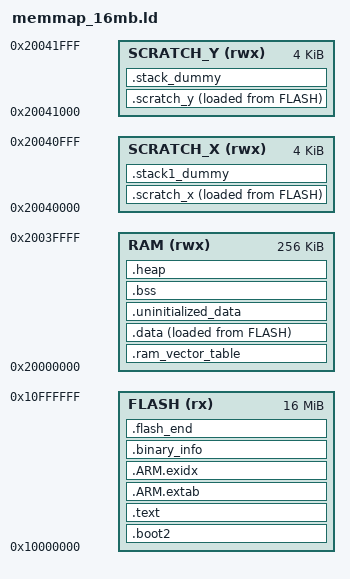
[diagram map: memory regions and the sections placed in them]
/* memmap_16mb.ld — Custom linker script for YD-RP2040 / WeAct RP2040
 * with 16 MB Flash (W25Q128JVSIQ or similar)
 *
 * Based on Pico SDK memmap_default.ld
 * Only change: FLASH LENGTH 2048k → 16384k
 */

MEMORY
{
    FLASH(rx) : ORIGIN = 0x10000000, LENGTH = 16384k
    RAM(rwx) : ORIGIN =  0x20000000, LENGTH = 256k
    SCRATCH_X(rwx) : ORIGIN = 0x20040000, LENGTH = 4k
    SCRATCH_Y(rwx) : ORIGIN = 0x20041000, LENGTH = 4k
}

ENTRY(_entry_point)

SECTIONS
{
    /* Second stage bootloader is prepended to the image. It must be 256 bytes big
       and checksummed with a specific algorithm. See boot_stage2 in the SDK. */
    .boot2 : {
        __boot2_start__ = .;
        KEEP (*(.boot2))
        __boot2_end__ = .;
    } > FLASH

    ASSERT(__boot2_end__ - __boot2_start__ == 256,
        "ERROR: Pico second stage bootloader must be 256 bytes in size")

    /* The second stage will always enter the image at the start of .text.
       The debugger will use the ELF entry point, which is the _entry_point
       symbol if present, otherwise defaults to start of .text.
       These must agree, so .text must start at its expected load address */
    .text : {
        __logical_binary_start = .;
        KEEP (*(.vectors))
        KEEP (*(.binary_info_header))
        __binary_info_header_end = .;
        KEEP (*(.embedded_block))
        __embedded_block_end = .;
        *(.time_critical*)
        *(.text*)
        . = ALIGN(4);
        *(.rodata*)
        . = ALIGN(4);
    } > FLASH

    .ARM.extab :
    {
        *(.ARM.extab* .gnu.linkonce.armextab.*)
    } > FLASH

    __exidx_start = .;
    .ARM.exidx :
    {
        *(.ARM.exidx* .gnu.linkonce.armexidx.*)
    } > FLASH
    __exidx_end = .;

    /* Machine inspectable binary information */
    . = ALIGN(4);
    __binary_info_start = .;
    .binary_info :
    {
        KEEP(*(.binary_info.keep.*))
        *(.binary_info.*)
    } > FLASH
    __binary_info_end = .;
    . = ALIGN(4);

    /* End of .text-like segments */
    __etext = .;

   .ram_vector_table (COPY): {
        *(.ram_vector_table)
    } > RAM

    .data : {
        __data_start__ = .;
        *(vtable)
        *(.data*)
        *(.after_data.*)
        . = ALIGN(4);
        /* preinit data */
        PROVIDE_HIDDEN (__mutex_array_start = .);
        KEEP(*(SORT(.mutex_array.*)))
        KEEP(*(.mutex_array))
        PROVIDE_HIDDEN (__mutex_array_end = .);

        PROVIDE_HIDDEN (__preinit_array_start = .);
        KEEP(*(SORT(.preinit_array.*)))
        KEEP(*(.preinit_array))
        PROVIDE_HIDDEN (__preinit_array_end = .);

        PROVIDE_HIDDEN (__init_array_start = .);
        KEEP(*(SORT(.init_array.*)))
        KEEP(*(.init_array))
        PROVIDE_HIDDEN (__init_array_end = .);

        PROVIDE_HIDDEN (__fini_array_start = .);
        KEEP(*(SORT(.fini_array.*)))
        KEEP(*(.fini_array))
        PROVIDE_HIDDEN (__fini_array_end = .);

        *(.jcr)
        . = ALIGN(4);
        /* All data end */
        __data_end__ = .;
    } > RAM AT> FLASH

    .uninitialized_data (COPY): {
        . = ALIGN(4);
        *(.uninitialized_data*)
    } > RAM

    /* Start and end symbols must be word-aligned */
    .scratch_x : {
        __scratch_x_start__ = .;
        *(.scratch_x.*)
        . = ALIGN(4);
        __scratch_x_end__ = .;
    } > SCRATCH_X AT > FLASH
    __scratch_x_source__ = LOADADDR(.scratch_x);

    .scratch_y : {
        __scratch_y_start__ = .;
        *(.scratch_y.*)
        . = ALIGN(4);
        __scratch_y_end__ = .;
    } > SCRATCH_Y AT > FLASH
    __scratch_y_source__ = LOADADDR(.scratch_y);

    .bss  : {
        . = ALIGN(4);
        __bss_start__ = .;
        *(SORT_BY_ALIGNMENT(SORT_BY_NAME(.bss*)))
        *(COMMON)
        . = ALIGN(4);
        __bss_end__ = .;
    } > RAM

    .heap (COPY):
    {
        __end__ = .;
        end = __end__;
        KEEP(*(.heap*))
        __HeapLimit = .;
    } > RAM

    /* .stack*_dummy section doesn't contains any symbols. It is only
     * used for linker to calculate size of stack sections, and assign
     * values to stack symbols later
     *
     * stack1 section may be empty/missing if platform_launch_core1 is not used */

    /* by default we put core 0 stack at the end of scratch Y, so that if core 1
     * stack is not used then all of SCRATCH_Y is available as normal RAM */
    .stack1_dummy (COPY):
    {
        *(.stack1*)
    } > SCRATCH_X
    .stack_dummy (COPY):
    {
        KEEP(*(.stack*))
    } > SCRATCH_Y

    .flash_end : {
        PROVIDE(__flash_binary_end = .);
    } > FLASH

    /* stack limit is poorly named, but historically is maximum heap ptr */
    __StackLimit = ORIGIN(RAM) + LENGTH(RAM);
    __StackTop = ORIGIN(SCRATCH_Y) + LENGTH(SCRATCH_Y);
    __StackOneTop = ORIGIN(SCRATCH_X) + LENGTH(SCRATCH_X);
    __StackBottom = __StackTop - SIZEOF(.stack_dummy);
    __StackOneBottom = __StackOneTop - SIZEOF(.stack1_dummy);
    PROVIDE(__stack = __StackTop);

    /* Check if data + heap + stack exceeds RAM limit */
    ASSERT(__StackLimit >= __HeapLimit, "region RAM overflowed")

    ASSERT( __binary_info_header_end - __logical_binary_start <= 256, "Binary info must be in first 256 bytes of the binary")
}
